# MDR32F23QI register map
Vendor: Milandr; File version: 1.0
CPU: CM0 r0p0, little endian, no MPU, no FPU, 2 interrupt priority bits
Registers are 32-bit, read-write, reset 0x0 unless marked. A register's access mark holds for its fields unless they carry their own. Offsets are from the block's base; [hi:lo] are bit positions; {n}, {i} and the like mark numbered series; 'fields as' and 'values as' point back to an identical list.

## MDR_RST_CLK — RST_CLK
Base 0x40020000
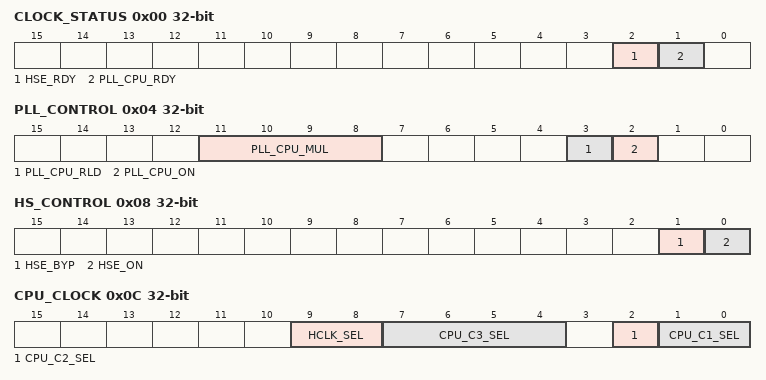
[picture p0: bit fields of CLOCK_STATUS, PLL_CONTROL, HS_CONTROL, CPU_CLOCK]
0x00 CLOCK_STATUS ro
  [2] HSE_RDY, [1] PLL_CPU_RDY
0x04 PLL_CONTROL
  [11:8] PLL_CPU_MUL, [3] PLL_CPU_RLD, [2] PLL_CPU_ON
0x08 HS_CONTROL
  [1] HSE_BYP, [0] HSE_ON
0x0C CPU_CLOCK
  [9:8] HCLK_SEL
    0=HSI (HSI selected); 1=CPU_C3 (CPU_C3 selected); 2=LSE (LSE selected); 3=LSI (LSI selected)
  [7:4] CPU_C3_SEL
  [2] CPU_C2_SEL
    0=CPU_C1 (CPU_C1 selected); 1=PLLCPUo selected
  [1:0] CPU_C1_SEL
    0=HSI (HSI selected); 1=HSI/2 (HSI/2 selected); 2=HSE (HSE selected); 3=HSE/2 (HSE/2 selected)
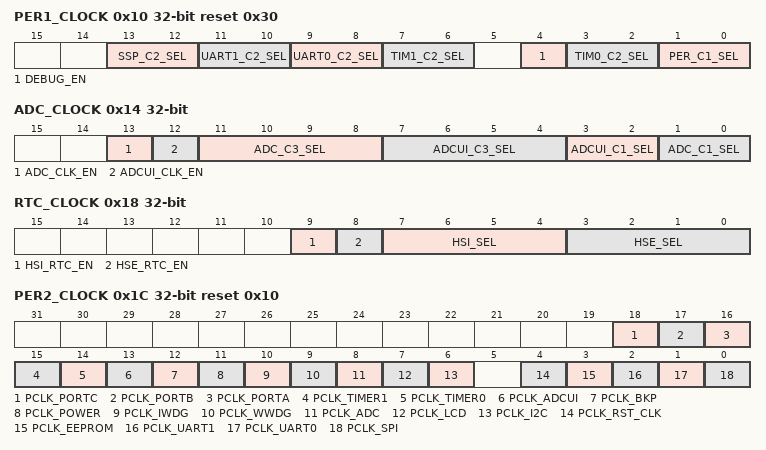
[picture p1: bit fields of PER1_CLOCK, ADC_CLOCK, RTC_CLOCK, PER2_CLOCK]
0x10 PER1_CLOCK reset 0x30
  [13:12] SSP_C2_SEL
    0=CPU_C1 (CPU_C1 selected); 1=PER1_C1 (PER1_C1 selected); 2=PLLCPUo selected; 3=HSI_CLK (HSI_CLK selected)
  [11:10] UART1_C2_SEL
    values as SSP_C2_SEL
  [9:8] UART0_C2_SEL
    values as SSP_C2_SEL
  [7:6] TIM1_C2_SEL
    values as SSP_C2_SEL
  [4] DEBUG_EN
  [3:2] TIM0_C2_SEL
    values as SSP_C2_SEL
  [1:0] PER_C1_SEL
    0=LSI (LSI selected); 1=LSI/2 (LSI/2 selected); 2=LSE (LSE selected); 3=LSE/2 (LSE/2 selected)
0x14 ADC_CLOCK
  [13] ADC_CLK_EN
  [12] ADCUI_CLK_EN
  [11:8] ADC_C3_SEL
  [7:4] ADCUI_C3_SEL
  [3:2] ADCUI_C1_SEL
    values as PER1_CLOCK.SSP_C2_SEL
  [1:0] ADC_C1_SEL
    values as PER1_CLOCK.SSP_C2_SEL
0x18 RTC_CLOCK
  [9] HSI_RTC_EN, [8] HSE_RTC_EN, [7:4] HSI_SEL, [3:0] HSE_SEL
0x1C PER2_CLOCK reset 0x10 — PER2 Clock Enable Register
  [18] PCLK_PORTC, [17] PCLK_PORTB, [16] PCLK_PORTA, [15] PCLK_TIMER1, [14] PCLK_TIMER0, [13] PCLK_ADCUI, [12] PCLK_BKP, [11] PCLK_POWER, [10] PCLK_IWDG, [9] PCLK_WWDG, [8] PCLK_ADC, [7] PCLK_LCD, [6] PCLK_I2C, [4] PCLK_RST_CLK, [3] PCLK_EEPROM, [2] PCLK_UART1, [1] PCLK_UART0, [0] PCLK_SPI
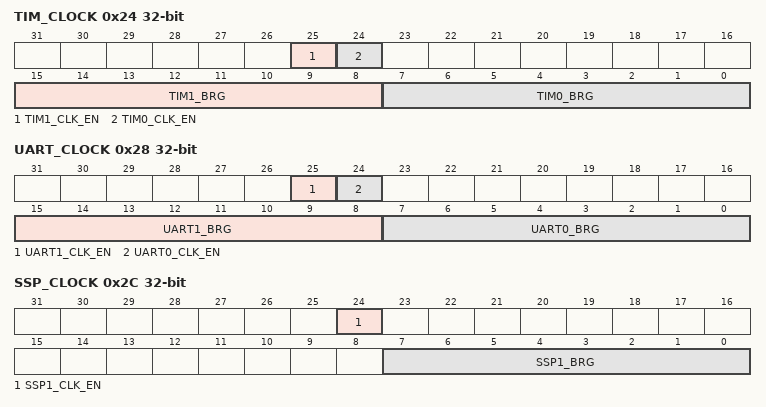
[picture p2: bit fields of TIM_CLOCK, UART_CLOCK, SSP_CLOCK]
0x24 TIM_CLOCK — Timer Clock Register
  [25] TIM1_CLK_EN, [24] TIM0_CLK_EN, [15:8] TIM1_BRG, [7:0] TIM0_BRG
0x28 UART_CLOCK
  [25] UART1_CLK_EN, [24] UART0_CLK_EN, [15:8] UART1_BRG, [7:0] UART0_BRG
0x2C SSP_CLOCK
  [24] SSP1_CLK_EN, [7:0] SSP1_BRG

## MDR_I2C — I2C interface controller registers
Base 0x40030000
0x00 PRL — I2C Prescaler (low byte) Register
  [7:0] PR
0x04 PRH — I2C Prescaler (high byte) Register
  [7:0] PR
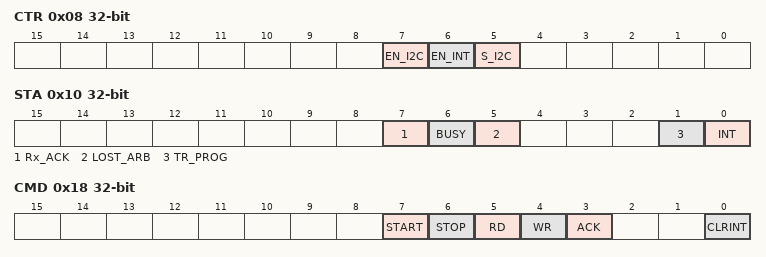
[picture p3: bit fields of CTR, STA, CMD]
0x08 CTR — I2C Control Register
  [7] EN_I2C, [6] EN_INT, [5] S_I2C
0x0C RXD — I2C Received Data Register
  [7:0] RXD
0x10 STA — I2C Status Register
  [7] Rx_ACK, [6] BUSY, [5] LOST_ARB, [1] TR_PROG, [0] INT
0x14 TXD — I2C Transmitted Data Register
  [7:0] TXD
0x18 CMD — I2C Command Register
  [7] START, [6] STOP, [5] RD, [4] WR, [3] ACK, [0] CLRINT

## MDR_LCD — LCD Display Controler
Base 0x40038000
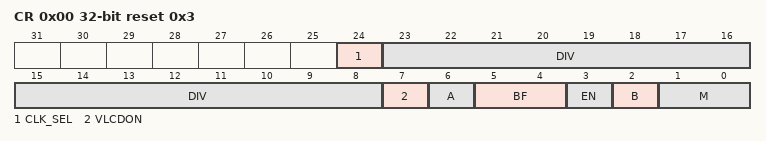
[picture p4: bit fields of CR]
0x00 CR reset 0x3 (reset mask 0xFFFFFF) — LCD Control register
  [24] CLK_SEL
    0=LSE (Clock from LSE); 1=LSI (Clock from LSI)
  [23:8] DIV
  [7] VLCDON
    0=Internal source; 1=External source
  [6] A
    0=BF (Flicker according to BF); 1=Alternative (Flicker according to alternative memory)
  [5:4] BF
    0=Off (Flicker Disabled); 1=2Hz (Flicker with 2 Hz); 2=1Hz (Flicker with 1 Hz); 3=0p5Hz (Flicker with 0.5 Hz)
  [3] EN
  [2] B
    0=div3 (Bias 1/3); 1=div2 (Bias 1/2)
  [1:0] M
    0=Static Control; 1=MUX_2 (Muxtiplexing 1:2); 2=MUX_3 (Muxtiplexing 1:3); 3=MUX_4 (Muxtiplexing 1:4)
{0x0+4i} ROW{i} (i=1..4) (reset mask 0x3FFFFFFF) — Base memory data string
{0x10+4i} AROW{i} (i=1..4) (reset mask 0x3FFFFFFF) — Alternative memory data string

## MDR_ADC — ADC
Base 0x40040000
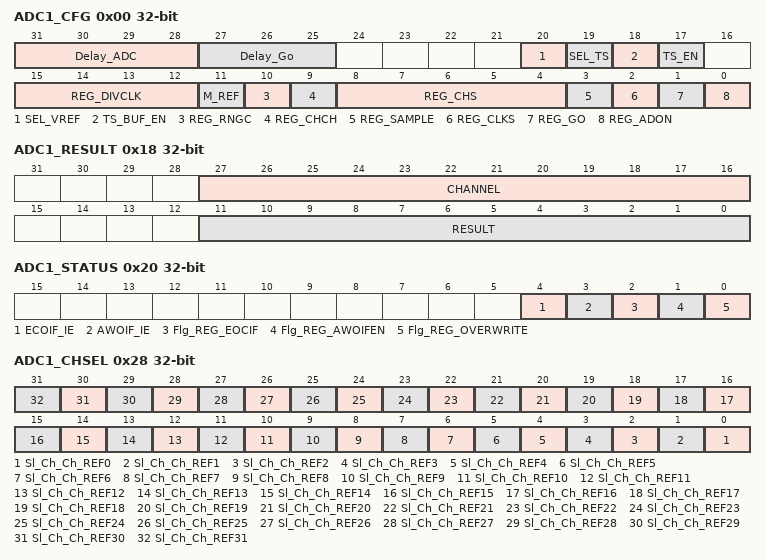
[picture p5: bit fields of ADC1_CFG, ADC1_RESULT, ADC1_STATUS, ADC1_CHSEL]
0x00 ADC1_CFG — ADC1 Configuration Register
  [31:28] Delay_ADC, [27:25] Delay_Go, [20] SEL_VREF, [19] SEL_TS, [18] TS_BUF_EN, [17] TS_EN, [15:12] REG_DIVCLK, [11] M_REF, [10] REG_RNGC, [9] REG_CHCH, [8:4] REG_CHS, [3] REG_SAMPLE, [2] REG_CLKS, [1] REG_GO, [0] REG_ADON
0x04 ADC2_CFG — ADC2 Configuration Register
  [17] ADC1_OP
0x08 ADC1_H_LEVEL — ADC1 High Level Register
  [11:0] REG_H_LEVEL
0x10 ADC1_L_LEVEL — ADC1 Low Level Register
  [11:0] REG_L_LEVEL
0x18 ADC1_RESULT
  [27:16] CHANNEL, [11:0] RESULT
0x20 ADC1_STATUS
  [4] ECOIF_IE, [3] AWOIF_IE, [2] Flg_REG_EOCIF, [1] Flg_REG_AWOIFEN, [0] Flg_REG_OVERWRITE
0x28 ADC1_CHSEL — ADC1 Channel Selector Register
  [n] Sl_Ch_Ch_REF{n} (n=0..31)
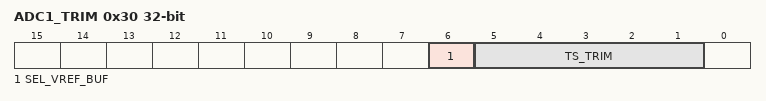
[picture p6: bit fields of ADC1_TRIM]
0x30 ADC1_TRIM
  [6] SEL_VREF_BUF, [5:1] TS_TRIM
